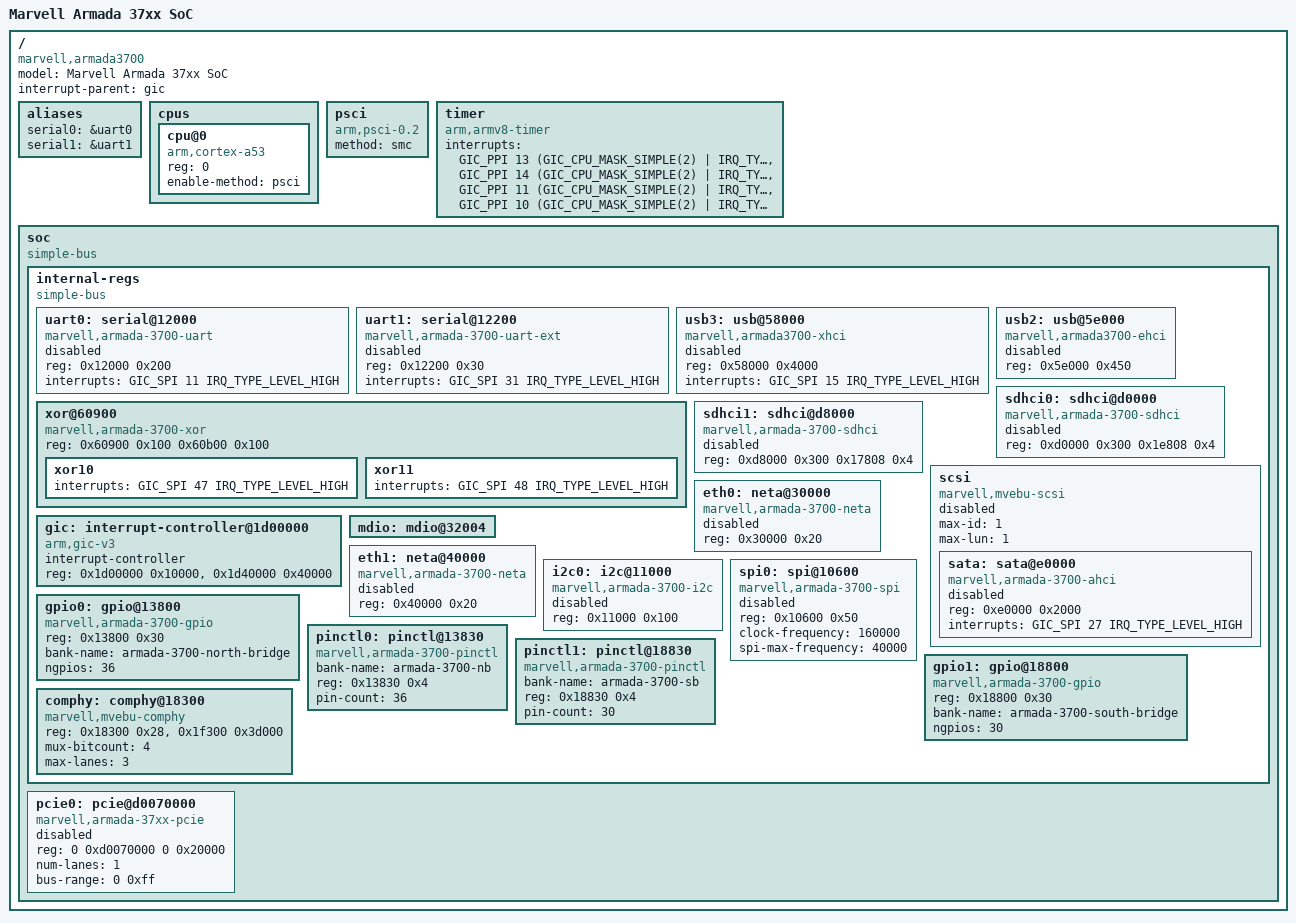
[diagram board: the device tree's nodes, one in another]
/*
 * Device Tree Include file for Marvell Armada 37xx family of SoCs.
 *
 * Copyright (C) 2016 Marvell
 *
 * Gregory CLEMENT <gregory.clement@free-electrons.com>
 *
 * This file is dual-licensed: you can use it either under the terms
 * of the GPL or the X11 license, at your option. Note that this dual
 * licensing only applies to this file, and not this project as a
 * whole.
 *
 *  a) This file is free software; you can redistribute it and/or
 *     modify it under the terms of the GNU General Public License as
 *     published by the Free Software Foundation; either version 2 of the
 *     License, or (at your option) any later version.
 *
 *     This file is distributed in the hope that it will be useful
 *     but WITHOUT ANY WARRANTY; without even the implied warranty of
 *     MERCHANTABILITY or FITNESS FOR A PARTICULAR PURPOSE.  See the
 *     GNU General Public License for more details.
 *
 * Or, alternatively
 *
 *  b) Permission is hereby granted, free of charge, to any person
 *     obtaining a copy of this software and associated documentation
 *     files (the "Software"), to deal in the Software without
 *     restriction, including without limitation the rights to use
 *     copy, modify, merge, publish, distribute, sublicense, and/or
 *     sell copies of the Software, and to permit persons to whom the
 *     Software is furnished to do so, subject to the following
 *     conditions:
 *
 *     The above copyright notice and this permission notice shall be
 *     included in all copies or substantial portions of the Software.
 *
 *     THE SOFTWARE IS PROVIDED , WITHOUT WARRANTY OF ANY KIND
 *     EXPRESS OR IMPLIED, INCLUDING BUT NOT LIMITED TO THE WARRANTIES
 *     OF MERCHANTABILITY, FITNESS FOR A PARTICULAR PURPOSE AND
 *     NONINFRINGEMENT. IN NO EVENT SHALL THE AUTHORS OR COPYRIGHT
 *     HOLDERS BE LIABLE FOR ANY CLAIM, DAMAGES OR OTHER LIABILITY
 *     WHETHER IN AN ACTION OF CONTRACT, TORT OR OTHERWISE, ARISING
 *     FROM, OUT OF OR IN CONNECTION WITH THE SOFTWARE OR THE USE OR
 *     OTHER DEALINGS IN THE SOFTWARE.
 */

#include <dt-bindings/interrupt-controller/arm-gic.h>
#include <dt-bindings/comphy/comphy_data.h>
#include <dt-bindings/gpio/gpio.h>

/ {
	model = "Marvell Armada 37xx SoC";
	compatible = "marvell,armada3700";
	interrupt-parent = <&gic>;
	#address-cells = <2>;
	#size-cells = <2>;

	aliases {
		serial0 = &uart0;
		serial1 = &uart1;
	};

	cpus {
		#address-cells = <1>;
		#size-cells = <0>;
		cpu@0 {
			device_type = "cpu";
			compatible = "arm,cortex-a53", "arm,armv8";
			reg = <0>;
			enable-method = "psci";
		};
	};

	psci {
		compatible = "arm,psci-0.2";
		method = "smc";
	};

	timer {
		compatible = "arm,armv8-timer";
		interrupts = <GIC_PPI 13
			(GIC_CPU_MASK_SIMPLE(2) | IRQ_TYPE_LEVEL_HIGH)>,
			     <GIC_PPI 14
			(GIC_CPU_MASK_SIMPLE(2) | IRQ_TYPE_LEVEL_HIGH)>,
			     <GIC_PPI 11
			(GIC_CPU_MASK_SIMPLE(2) | IRQ_TYPE_LEVEL_HIGH)>,
			     <GIC_PPI 10
			(GIC_CPU_MASK_SIMPLE(2) | IRQ_TYPE_LEVEL_HIGH)>;
	};

	soc {
		compatible = "simple-bus";
		#address-cells = <2>;
		#size-cells = <2>;
		ranges;

		internal-regs {
			#address-cells = <1>;
			#size-cells = <1>;
			compatible = "simple-bus";
			/* 32M internal register @ 0xd000_0000 */
			ranges = <0x0 0x0 0xd0000000 0x2000000>;

			uart0: serial@12000 {
				compatible = "marvell,armada-3700-uart";
				reg = <0x12000 0x200>;
				interrupts = <GIC_SPI 11 IRQ_TYPE_LEVEL_HIGH>;
				status = "disabled";
			};

			uart1: serial@12200 {
				compatible = "marvell,armada-3700-uart-ext";
				reg = <0x12200 0x30>;
				interrupts = <GIC_SPI 31 IRQ_TYPE_LEVEL_HIGH>;
				status = "disabled";
			};

			usb3: usb@58000 {
				compatible = "marvell,armada3700-xhci",
				"generic-xhci";
				reg = <0x58000 0x4000>;
				interrupts = <GIC_SPI 15 IRQ_TYPE_LEVEL_HIGH>;
				status = "disabled";
			};

			usb2: usb@5e000 {
				compatible = "marvell,armada3700-ehci";
				reg = <0x5e000 0x450>;
				status = "disabled";
			};

			xor@60900 {
				compatible = "marvell,armada-3700-xor";
				reg = <0x60900 0x100
				       0x60b00 0x100>;

				xor10 {
					interrupts = <GIC_SPI 47 IRQ_TYPE_LEVEL_HIGH>;
				};
				xor11 {
					interrupts = <GIC_SPI 48 IRQ_TYPE_LEVEL_HIGH>;
				};
			};

			sdhci0: sdhci@d0000 {
				compatible = "marvell,armada-3700-sdhci",
				"marvell,sdhci-xenon";
				reg = <0xd0000 0x300
				       0x1e808 0x4>;
				status = "disabled";
			};

			sdhci1: sdhci@d8000 {
				compatible = "marvell,armada-3700-sdhci",
				"marvell,sdhci-xenon";
				reg = <0xd8000 0x300
				       0x17808 0x4>;
				status = "disabled";
			};

			scsi: scsi {
				compatible = "marvell,mvebu-scsi";
				#address-cells = <1>;
				#size-cells = <1>;
				max-id = <1>;
				max-lun = <1>;
				status = "disabled";
				sata: sata@e0000 {
					compatible = "marvell,armada-3700-ahci";
					reg = <0xe0000 0x2000>;
					interrupts = <GIC_SPI 27 IRQ_TYPE_LEVEL_HIGH>;
					status = "disabled";
				};
			};

			gic: interrupt-controller@1d00000 {
				compatible = "arm,gic-v3";
				#interrupt-cells = <3>;
				interrupt-controller;
				reg = <0x1d00000 0x10000>, /* GICD */
				      <0x1d40000 0x40000>; /* GICR */
			};

			eth0: neta@30000 {
				compatible = "marvell,armada-3700-neta";
				reg = <0x30000 0x20>;
				status = "disabled";
			};

			mdio: mdio@32004 {
				#address-cells = <1>;
				#size-cells = <0>;
			};

			eth1: neta@40000 {
				compatible = "marvell,armada-3700-neta";
				reg = <0x40000 0x20>;
				status = "disabled";
			};

			i2c0: i2c@11000 {
				compatible = "marvell,armada-3700-i2c", "simple-bus";
				#address-cells = <1>;
				#size-cells = <0>;
				reg = <0x11000 0x100>;
				status = "disabled";
			};

			spi0: spi@10600 {
				compatible = "marvell,armada-3700-spi";
				reg = <0x10600 0x50>;
				#address-cells = <1>;
				#size-cells = <0>;
				#clock-cells = <0>;
				clock-frequency = <160000>;
				spi-max-frequency = <40000>;
				status = "disabled";
			};

			gpio0: gpio@13800 {
				compatible = "marvell,armada-3700-gpio";
				#gpio-cells = <2>;
				reg = <0x13800 0x30>;
				bank-name = "armada-3700-north-bridge";
				ngpios = <36>;
				status = "okay";
			};

			pinctl0: pinctl@13830 { /* north bridge */
				compatible = "marvell,armada-3700-pinctl";
				bank-name = "armada-3700-nb";
				reg = <0x13830 0x4>;
				pin-count = <36>;
			};

			gpio1: gpio@18800 {
				compatible = "marvell,armada-3700-gpio";
				#gpio-cells = <2>;
				reg = <0x18800 0x30>;
				bank-name = "armada-3700-south-bridge";
				ngpios = <30>;
				status = "okay";
			};

			pinctl1: pinctl@18830 { /* south bridge */
				compatible = "marvell,armada-3700-pinctl";
				bank-name = "armada-3700-sb";
				reg = <0x18830 0x4>;
				pin-count = <30>;
			};

			comphy: comphy@18300 {
				compatible = "marvell,mvebu-comphy", "marvell,comphy-armada-3700";
				reg = <0x18300 0x28>,
				      <0x1f300 0x3d000>;
				mux-bitcount = <4>;
				max-lanes = <3>;
			};
		};

		pcie0: pcie@d0070000 {
			compatible = "marvell,armada-37xx-pcie";
			reg = <0 0xd0070000 0 0x20000>;
			#address-cells = <3>;
			#size-cells = <2>;
			device_type = "pci";
			num-lanes = <1>;
			status = "disabled";

			bus-range = <0 0xff>;
			ranges = <0x82000000 0 0xd8200000   0 0xd8200000 0 0x1000000 /* Port 0 MEM */
				  0x81000000 0 0xd9200000   0 0xd9200000 0 0x10000>; /* Port 0 IO*/
		};
	};
};
